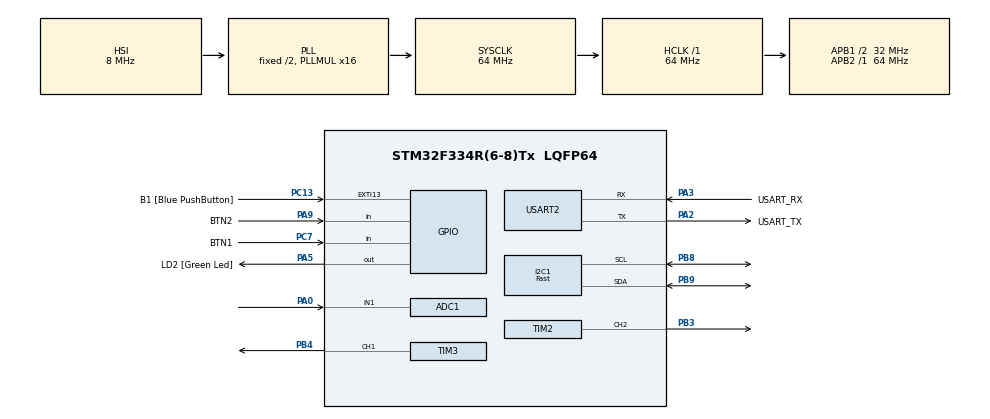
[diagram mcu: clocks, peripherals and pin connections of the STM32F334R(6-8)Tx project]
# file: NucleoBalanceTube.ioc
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ADC1.Channel-0\#ChannelRegularConversion=ADC_CHANNEL_1
ADC1.ContinuousConvMode=ENABLE
ADC1.NbrOfConversionFlag=1
ADC1.Offset-0\#ChannelRegularConversion=0
ADC1.OffsetNumber-0\#ChannelRegularConversion=ADC_OFFSET_NONE
ADC1.Rank-0\#ChannelRegularConversion=1
ADC1.SamplingTime-0\#ChannelRegularConversion=ADC_SAMPLETIME_1CYCLE_5
ADC1.SamplingTimeOPAMP-0\#ChannelRegularConversion=ADC_SAMPLETIME_61CYCLES_5
ADC1.SubFamily=STM32F334x8
ADC1.master=1
Dma.Request0=TIM3_CH1/TRIG
Dma.TIM3_CH1/TRIG.0.Direction=DMA_MEMORY_TO_PERIPH
Dma.TIM3_CH1/TRIG.0.Instance=DMA1_Channel6
Dma.TIM3_CH1/TRIG.0.MemDataAlignment=DMA_MDATAALIGN_WORD
Dma.TIM3_CH1/TRIG.0.MemInc=DMA_MINC_ENABLE
Dma.TIM3_CH1/TRIG.0.Mode=DMA_NORMAL
Dma.TIM3_CH1/TRIG.0.PeriphDataAlignment=DMA_PDATAALIGN_WORD
Dma.TIM3_CH1/TRIG.0.PeriphInc=DMA_PINC_DISABLE
Dma.TIM3_CH1/TRIG.0.Priority=DMA_PRIORITY_VERY_HIGH
I2C1.I2C_Speed_Mode=I2C_Fast
I2C1.Timing=0x0000020B
Mcu.Family=STM32F3
Mcu.Name=STM32F334R(6-8)Tx
Mcu.Package=LQFP64
NVIC.DMA1_Channel6_IRQn=true\:0\:0\:false\:false\:true\:false\:true\:true
NVIC.PriorityGroup=NVIC_PRIORITYGROUP_4
NVIC.TIM6_DAC1_IRQn=true\:1\:0\:true\:false\:true\:true\:true\:true
PA0.Mode=IN1-Single-Ended
PA0.Signal=ADC1_IN1
PA13.GPIO_Label=TMS
PA13.Mode=Serial_Wire
PA13.Signal=SYS_JTMS-SWDIO
PA14.GPIO_Label=TCK
PA14.Mode=Serial_Wire
PA14.Signal=SYS_JTCK-SWCLK
PA2.GPIO_Label=USART_TX
PA2.Mode=Asynchronous
PA2.Signal=USART2_TX
PA3.GPIO_Label=USART_RX
PA3.Mode=Asynchronous
PA3.Signal=USART2_RX
PA5.GPIO_Label=LD2 [Green Led]
PA5.Signal=GPIO_Output
PA9.GPIO_Label=BTN2
PA9.GPIO_PuPd=GPIO_PULLUP
PA9.Signal=GPIO_Input
PB3.Signal=S_TIM2_CH2
PB4.Signal=S_TIM3_CH1
PB8.Mode=I2C
PB8.Signal=I2C1_SCL
PB9.Mode=I2C
PB9.Signal=I2C1_SDA
PC13.GPIO_Label=B1 [Blue PushButton]
PC13.GPIO_ModeDefaultEXTI=GPIO_MODE_IT_FALLING
PC13.Signal=GPXTI13
PC14\ /\ OSC32_IN.Mode=LSE-External-Oscillator
PC14\ /\ OSC32_IN.Signal=RCC_OSC32_IN
PC15\ /\ OSC32_OUT.GPIO_Label=RCC_OSC32_OUT
PC15\ /\ OSC32_OUT.Mode=LSE-External-Oscillator
PC15\ /\ OSC32_OUT.Signal=RCC_OSC32_OUT
PC7.GPIO_Label=BTN1
PC7.GPIO_PuPd=GPIO_PULLUP
PC7.Signal=GPIO_Input
PF0\ /\ OSC_IN.Mode=HSE-External-Clock-Source
PF0\ /\ OSC_IN.Signal=RCC_OSC_IN
PF1\ /\ OSC_OUT.Signal=RCC_OSC_OUT
ProjectManager.HeapSize=0x200
ProjectManager.StackSize=0x400
ProjectManager.TargetToolchain=STM32CubeIDE
RCC.AHBFreq_Value=64000000
RCC.APB1CLKDivider=RCC_HCLK_DIV2
RCC.APB1Freq_Value=32000000
RCC.APB1TimFreq_Value=64000000
RCC.APB2Freq_Value=64000000
RCC.APB2TimFreq_Value=64000000
RCC.CortexFreq_Value=64000000
RCC.FLatency-AdvancedSettings=FLASH_LATENCY_2
RCC.HCLKFreq_Value=64000000
RCC.HSE_VALUE=8000000
RCC.HSI_VALUE=8000000
RCC.PLLMUL=RCC_PLL_MUL16
RCC.SYSCLKFreq_VALUE=64000000
RCC.SYSCLKSourceVirtual=RCC_SYSCLKSOURCE_PLLCLK
SH.S_TIM2_CH2.0=TIM2_CH2,PWM Generation2 CH2
SH.S_TIM3_CH1.0=TIM3_CH1,PWM Generation1 CH1
TIM2.AutoReloadPreload=TIM_AUTORELOAD_PRELOAD_ENABLE
TIM2.Channel-PWM\ Generation2\ CH2=TIM_CHANNEL_2
TIM2.Period=63999
TIM2.Prescaler=19
TIM3.Channel-PWM\ Generation1\ CH1=TIM_CHANNEL_1
TIM3.Period=76
TIM6.Period=1000
TIM6.Prescaler=63
USART2.VirtualMode-Asynchronous=VM_ASYNC
VP_TIM6_VS_ClockSourceINT.Mode=Enable_Timer
board=NUCLEO-F334R8

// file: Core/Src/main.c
/* USER CODE BEGIN Header */
/**
 ******************************************************************************
 * @file           : main.c
 * @brief          : Main program body
 ******************************************************************************
 * @attention
 *
 * Copyright (c) 2024 STMicroelectronics.
 * All rights reserved.
 *
 * This software is licensed under terms that can be found in the LICENSE file
 * in the root directory of this software component.
 * If no LICENSE file comes with this software, it is provided AS-IS.
 *
 ******************************************************************************
 */
/* USER CODE END Header */
#include "main.h"

/* USER CODE BEGIN Includes */

#include "BalanceTube.h"

/* USER CODE END Includes */

ADC_HandleTypeDef hadc1;

I2C_HandleTypeDef hi2c1;

TIM_HandleTypeDef htim2;
TIM_HandleTypeDef htim3;
TIM_HandleTypeDef htim6;
DMA_HandleTypeDef hdma_tim3_ch1_trig;

UART_HandleTypeDef huart2;

void SystemClock_Config(void);
static void MX_GPIO_Init(void);
static void MX_DMA_Init(void);
static void MX_USART2_UART_Init(void);
static void MX_TIM2_Init(void);
static void MX_I2C1_Init(void);
static void MX_ADC1_Init(void);
static void MX_TIM3_Init(void);
static void MX_TIM6_Init(void);

int main(void) {

	/* MCU Configuration--------------------------------------------------------*/

	/* Reset of all peripherals, Initializes the Flash interface and the Systick. */
	HAL_Init();

	/* Configure the system clock */
	SystemClock_Config();

	/* Initialize all configured peripherals */
	MX_GPIO_Init();
	MX_DMA_Init();
	MX_USART2_UART_Init();
	MX_TIM2_Init();
	MX_I2C1_Init();
	MX_ADC1_Init();
	MX_TIM3_Init();
	MX_TIM6_Init();
	/* USER CODE BEGIN 2 */
	initializeBalanceTube();
	/* USER CODE END 2 */

	/* Infinite loop */
	/* USER CODE BEGIN WHILE */
	while (1) {
		runBalanceTube();
		/* USER CODE END WHILE */

	}
}

void SystemClock_Config(void) {
	RCC_OscInitTypeDef RCC_OscInitStruct = { 0 };
	RCC_ClkInitTypeDef RCC_ClkInitStruct = { 0 };
	RCC_PeriphCLKInitTypeDef PeriphClkInit = { 0 };

	/** Initializes the RCC Oscillators according to the specified parameters
	 * in the RCC_OscInitTypeDef structure.
	 */
	RCC_OscInitStruct.OscillatorType = RCC_OSCILLATORTYPE_HSI;
	RCC_OscInitStruct.HSIState = RCC_HSI_ON;
	RCC_OscInitStruct.HSICalibrationValue = RCC_HSICALIBRATION_DEFAULT;
	RCC_OscInitStruct.PLL.PLLState = RCC_PLL_ON;
	RCC_OscInitStruct.PLL.PLLSource = RCC_PLLSOURCE_HSI;
	RCC_OscInitStruct.PLL.PLLMUL = RCC_PLL_MUL16;
	if (HAL_RCC_OscConfig(&RCC_OscInitStruct) != HAL_OK) {
		Error_Handler();
	}

	/** Initializes the CPU, AHB and APB buses clocks
	 */
	RCC_ClkInitStruct.ClockType = RCC_CLOCKTYPE_HCLK | RCC_CLOCKTYPE_SYSCLK
			| RCC_CLOCKTYPE_PCLK1 | RCC_CLOCKTYPE_PCLK2;
	RCC_ClkInitStruct.SYSCLKSource = RCC_SYSCLKSOURCE_PLLCLK;
	RCC_ClkInitStruct.AHBCLKDivider = RCC_SYSCLK_DIV1;
	RCC_ClkInitStruct.APB1CLKDivider = RCC_HCLK_DIV2;
	RCC_ClkInitStruct.APB2CLKDivider = RCC_HCLK_DIV1;

	if (HAL_RCC_ClockConfig(&RCC_ClkInitStruct, FLASH_LATENCY_2) != HAL_OK) {
		Error_Handler();
	}
	PeriphClkInit.PeriphClockSelection = RCC_PERIPHCLK_I2C1
			| RCC_PERIPHCLK_ADC12;
	PeriphClkInit.Adc12ClockSelection = RCC_ADC12PLLCLK_DIV1;
	PeriphClkInit.I2c1ClockSelection = RCC_I2C1CLKSOURCE_HSI;
	if (HAL_RCCEx_PeriphCLKConfig(&PeriphClkInit) != HAL_OK) {
		Error_Handler();
	}
}

static void MX_ADC1_Init(void) {

	ADC_MultiModeTypeDef multimode = { 0 };
	ADC_ChannelConfTypeDef sConfig = { 0 };

	/** Common config
	 */
	hadc1.Instance = ADC1;
	hadc1.Init.ClockPrescaler = ADC_CLOCK_ASYNC_DIV1;
	hadc1.Init.Resolution = ADC_RESOLUTION_12B;
	hadc1.Init.ScanConvMode = ADC_SCAN_DISABLE;
	hadc1.Init.ContinuousConvMode = ENABLE;
	hadc1.Init.DiscontinuousConvMode = DISABLE;
	hadc1.Init.ExternalTrigConvEdge = ADC_EXTERNALTRIGCONVEDGE_NONE;
	hadc1.Init.ExternalTrigConv = ADC_SOFTWARE_START;
	hadc1.Init.DataAlign = ADC_DATAALIGN_RIGHT;
	hadc1.Init.NbrOfConversion = 1;
	hadc1.Init.DMAContinuousRequests = DISABLE;
	hadc1.Init.EOCSelection = ADC_EOC_SINGLE_CONV;
	hadc1.Init.LowPowerAutoWait = DISABLE;
	hadc1.Init.Overrun = ADC_OVR_DATA_OVERWRITTEN;
	if (HAL_ADC_Init(&hadc1) != HAL_OK) {
		Error_Handler();
	}

	/** Configure the ADC multi-mode
	 */
	multimode.Mode = ADC_MODE_INDEPENDENT;
	if (HAL_ADCEx_MultiModeConfigChannel(&hadc1, &multimode) != HAL_OK) {
		Error_Handler();
	}

	/** Configure Regular Channel
	 */
	sConfig.Channel = ADC_CHANNEL_1;
	sConfig.Rank = ADC_REGULAR_RANK_1;
	sConfig.SingleDiff = ADC_SINGLE_ENDED;
	sConfig.SamplingTime = ADC_SAMPLETIME_1CYCLE_5;
	sConfig.OffsetNumber = ADC_OFFSET_NONE;
	sConfig.Offset = 0;
	if (HAL_ADC_ConfigChannel(&hadc1, &sConfig) != HAL_OK) {
		Error_Handler();
	}

}

static void MX_I2C1_Init(void) {

	hi2c1.Instance = I2C1;
	hi2c1.Init.Timing = 0x0000020B;
	hi2c1.Init.OwnAddress1 = 0;
	hi2c1.Init.AddressingMode = I2C_ADDRESSINGMODE_7BIT;
	hi2c1.Init.DualAddressMode = I2C_DUALADDRESS_DISABLE;
	hi2c1.Init.OwnAddress2 = 0;
	hi2c1.Init.OwnAddress2Masks = I2C_OA2_NOMASK;
	hi2c1.Init.GeneralCallMode = I2C_GENERALCALL_DISABLE;
	hi2c1.Init.NoStretchMode = I2C_NOSTRETCH_DISABLE;
	if (HAL_I2C_Init(&hi2c1) != HAL_OK) {
		Error_Handler();
	}

	/** Configure Analogue filter
	 */
	if (HAL_I2CEx_ConfigAnalogFilter(&hi2c1, I2C_ANALOGFILTER_ENABLE)
			!= HAL_OK) {
		Error_Handler();
	}

	/** Configure Digital filter
	 */
	if (HAL_I2CEx_ConfigDigitalFilter(&hi2c1, 0) != HAL_OK) {
		Error_Handler();
	}

}

static void MX_TIM2_Init(void) {

	TIM_MasterConfigTypeDef sMasterConfig = { 0 };
	TIM_OC_InitTypeDef sConfigOC = { 0 };

	htim2.Instance = TIM2;
	htim2.Init.Prescaler = 19;
	htim2.Init.CounterMode = TIM_COUNTERMODE_UP;
	htim2.Init.Period = 63999;
	htim2.Init.ClockDivision = TIM_CLOCKDIVISION_DIV1;
	htim2.Init.AutoReloadPreload = TIM_AUTORELOAD_PRELOAD_ENABLE;
	if (HAL_TIM_PWM_Init(&htim2) != HAL_OK) {
		Error_Handler();
	}
	sMasterConfig.MasterOutputTrigger = TIM_TRGO_RESET;
	sMasterConfig.MasterSlaveMode = TIM_MASTERSLAVEMODE_DISABLE;
	if (HAL_TIMEx_MasterConfigSynchronization(&htim2, &sMasterConfig)
			!= HAL_OK) {
		Error_Handler();
	}
	sConfigOC.OCMode = TIM_OCMODE_PWM1;
	sConfigOC.Pulse = 0;
	sConfigOC.OCPolarity = TIM_OCPOLARITY_HIGH;
	sConfigOC.OCFastMode = TIM_OCFAST_DISABLE;
	if (HAL_TIM_PWM_ConfigChannel(&htim2, &sConfigOC, TIM_CHANNEL_2)
			!= HAL_OK) {
		Error_Handler();
	}
	HAL_TIM_MspPostInit(&htim2);

}

static void MX_TIM3_Init(void) {

	TIM_MasterConfigTypeDef sMasterConfig = { 0 };
	TIM_OC_InitTypeDef sConfigOC = { 0 };

	htim3.Instance = TIM3;
	htim3.Init.Prescaler = 0;
	htim3.Init.CounterMode = TIM_COUNTERMODE_UP;
	htim3.Init.Period = 76;
	htim3.Init.ClockDivision = TIM_CLOCKDIVISION_DIV1;
	htim3.Init.AutoReloadPreload = TIM_AUTORELOAD_PRELOAD_DISABLE;
	if (HAL_TIM_PWM_Init(&htim3) != HAL_OK) {
		Error_Handler();
	}
	sMasterConfig.MasterOutputTrigger = TIM_TRGO_RESET;
	sMasterConfig.MasterSlaveMode = TIM_MASTERSLAVEMODE_DISABLE;
	if (HAL_TIMEx_MasterConfigSynchronization(&htim3, &sMasterConfig)
			!= HAL_OK) {
		Error_Handler();
	}
	sConfigOC.OCMode = TIM_OCMODE_PWM1;
	sConfigOC.Pulse = 0;
	sConfigOC.OCPolarity = TIM_OCPOLARITY_HIGH;
	sConfigOC.OCFastMode = TIM_OCFAST_DISABLE;
	if (HAL_TIM_PWM_ConfigChannel(&htim3, &sConfigOC, TIM_CHANNEL_1)
			!= HAL_OK) {
		Error_Handler();
	}
	HAL_TIM_MspPostInit(&htim3);

}

static void MX_TIM6_Init(void) {

	TIM_MasterConfigTypeDef sMasterConfig = { 0 };

	htim6.Instance = TIM6;
	htim6.Init.Prescaler = 63;
	htim6.Init.CounterMode = TIM_COUNTERMODE_UP;
	htim6.Init.Period = 1000;
	htim6.Init.AutoReloadPreload = TIM_AUTORELOAD_PRELOAD_DISABLE;
	if (HAL_TIM_Base_Init(&htim6) != HAL_OK) {
		Error_Handler();
	}
	sMasterConfig.MasterOutputTrigger = TIM_TRGO_RESET;
	sMasterConfig.MasterSlaveMode = TIM_MASTERSLAVEMODE_DISABLE;
	if (HAL_TIMEx_MasterConfigSynchronization(&htim6, &sMasterConfig)
			!= HAL_OK) {
		Error_Handler();
	}

}

static void MX_USART2_UART_Init(void) {

	huart2.Instance = USART2;
	huart2.Init.BaudRate = 38400;
	huart2.Init.WordLength = UART_WORDLENGTH_8B;
	huart2.Init.StopBits = UART_STOPBITS_1;
	huart2.Init.Parity = UART_PARITY_NONE;
	huart2.Init.Mode = UART_MODE_TX_RX;
	huart2.Init.HwFlowCtl = UART_HWCONTROL_NONE;
	huart2.Init.OverSampling = UART_OVERSAMPLING_16;
	huart2.Init.OneBitSampling = UART_ONE_BIT_SAMPLE_DISABLE;
	huart2.AdvancedInit.AdvFeatureInit = UART_ADVFEATURE_NO_INIT;
	if (HAL_UART_Init(&huart2) != HAL_OK) {
		Error_Handler();
	}

}

static void MX_DMA_Init(void) {

	/* DMA controller clock enable */
	__HAL_RCC_DMA1_CLK_ENABLE();

	/* DMA interrupt init */
	/* DMA1_Channel6_IRQn interrupt configuration */
	HAL_NVIC_SetPriority(DMA1_Channel6_IRQn, 0, 0);
	HAL_NVIC_EnableIRQ(DMA1_Channel6_IRQn);

}

static void MX_GPIO_Init(void) {
	GPIO_InitTypeDef GPIO_InitStruct = { 0 };

	/* GPIO Ports Clock Enable */
	__HAL_RCC_GPIOC_CLK_ENABLE();
	__HAL_RCC_GPIOF_CLK_ENABLE();
	__HAL_RCC_GPIOA_CLK_ENABLE();
	__HAL_RCC_GPIOB_CLK_ENABLE();

	/*Configure GPIO pin Output Level */
	HAL_GPIO_WritePin(LD2_GPIO_Port, LD2_Pin, GPIO_PIN_RESET);

	/*Configure GPIO pin : B1_Pin */
	GPIO_InitStruct.Pin = B1_Pin;
	GPIO_InitStruct.Mode = GPIO_MODE_IT_FALLING;
	GPIO_InitStruct.Pull = GPIO_NOPULL;
	HAL_GPIO_Init(B1_GPIO_Port, &GPIO_InitStruct);

	/*Configure GPIO pin : LD2_Pin */
	GPIO_InitStruct.Pin = LD2_Pin;
	GPIO_InitStruct.Mode = GPIO_MODE_OUTPUT_PP;
	GPIO_InitStruct.Pull = GPIO_NOPULL;
	GPIO_InitStruct.Speed = GPIO_SPEED_FREQ_LOW;
	HAL_GPIO_Init(LD2_GPIO_Port, &GPIO_InitStruct);

	/*Configure GPIO pin : BTN1_Pin */
	GPIO_InitStruct.Pin = BTN1_Pin;
	GPIO_InitStruct.Mode = GPIO_MODE_INPUT;
	GPIO_InitStruct.Pull = GPIO_PULLUP;
	HAL_GPIO_Init(BTN1_GPIO_Port, &GPIO_InitStruct);

	/*Configure GPIO pin : BTN2_Pin */
	GPIO_InitStruct.Pin = BTN2_Pin;
	GPIO_InitStruct.Mode = GPIO_MODE_INPUT;
	GPIO_InitStruct.Pull = GPIO_PULLUP;
	HAL_GPIO_Init(BTN2_GPIO_Port, &GPIO_InitStruct);

}

void Error_Handler(void) {
	__disable_irq();
	while (1) {
	}
}
